VERSION ""

NS_ :

BS_:

BU_: AL DSC DSC_Sensor SZL

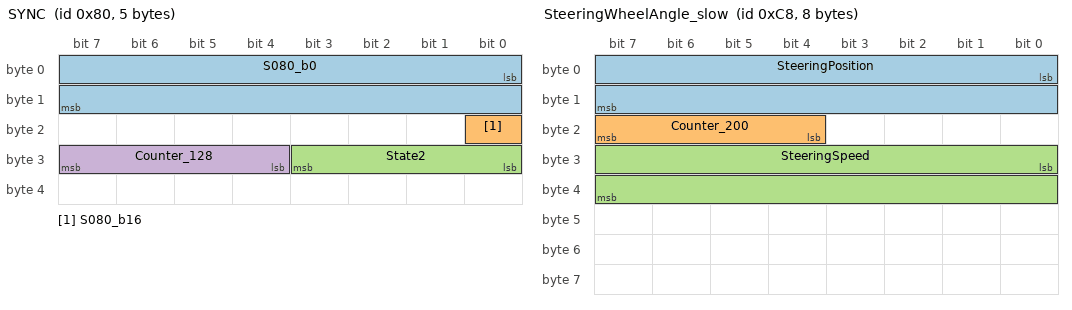
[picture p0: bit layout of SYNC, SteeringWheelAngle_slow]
BO_ 128 SYNC: 5 DSC
 SG_ S080_b0 : 0|16@1+ (1,0) [0|65535] "" Vector__XXX
 SG_ S080_b16 : 16|1@1+ (1,0) [0|1] "" Vector__XXX
 SG_ State2 : 24|4@1+ (1,0) [0|15] "" Vector__XXX
 SG_ Counter_128 : 28|4@1+ (1,0) [0|15] "" Vector__XXX

BO_ 195 SteeringWheelAngle_raw: 8 SZL

BO_ 200 SteeringWheelAngle_slow: 8 SZL
 SG_ SteeringPosition : 0|16@1- (0.04395,0) [-1440.1536|1440.10965] "deg" DSC
 SG_ Counter_200 : 20|4@1+ (1,0) [0|15] "" DSC
 SG_ SteeringSpeed : 24|16@1- (0.04395,0) [-1440.1536|1440.10965] "deg/s" DSC

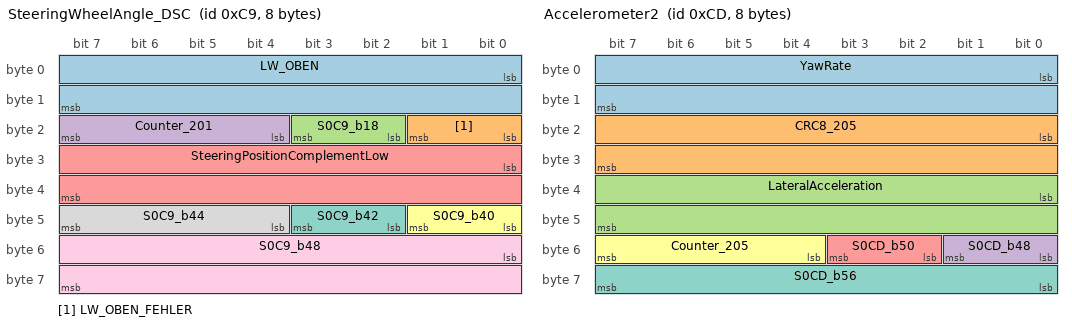
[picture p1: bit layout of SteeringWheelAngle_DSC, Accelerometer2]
BO_ 201 SteeringWheelAngle_DSC: 8 SZL
 SG_ LW_OBEN : 0|16@1- (0.04395,0) [-1440.1536|1440.10965] "deg" DSC
 SG_ LW_OBEN_FEHLER : 16|2@1+ (1,0) [0|3] "" DSC
 SG_ S0C9_b18 : 18|2@1+ (1,0) [0|3] "" DSC
 SG_ Counter_201 : 20|4@1+ (1,0) [0|15] "" DSC
 SG_ SteeringPositionComplementLow : 24|16@1- (1,0) [-32768|32767] "" DSC
 SG_ S0C9_b40 : 40|2@1+ (1,0) [0|3] "" DSC
 SG_ S0C9_b42 : 42|2@1+ (1,0) [0|3] "" DSC
 SG_ S0C9_b44 : 44|4@1+ (1,0) [0|15] "" DSC
 SG_ S0C9_b48 : 48|16@1+ (1,0) [0|65535] "" DSC

BO_ 205 Accelerometer2: 8 DSC_Sensor
 SG_ YawRate : 0|16@1- (1,0) [0|255] "" DSC
 SG_ CRC8_205 : 16|16@1- (1,0) [0|65535] "" DSC
 SG_ LateralAcceleration : 32|16@1- (1,0) [0|255] "" DSC
 SG_ S0CD_b48 : 48|2@1+ (1,0) [0|3] "" DSC
 SG_ S0CD_b50 : 50|2@1+ (1,0) [0|3] "" DSC
 SG_ Counter_205 : 52|4@1+ (1,0) [0|255] "" DSC
 SG_ S0CD_b56 : 56|8@1+ (1,0) [0|255] "" DSC

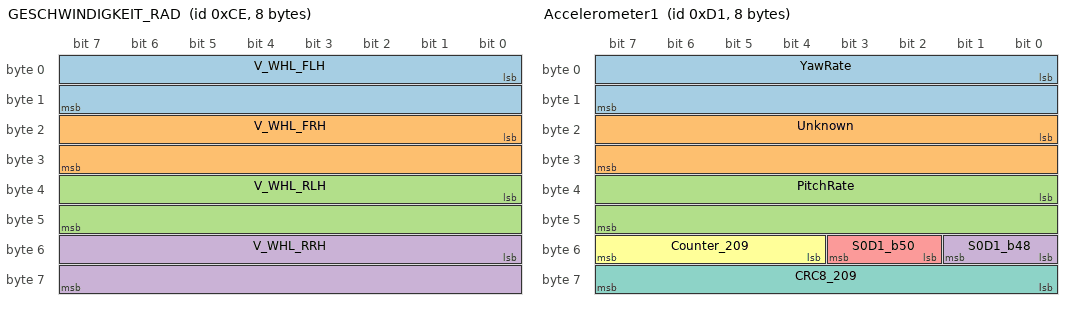
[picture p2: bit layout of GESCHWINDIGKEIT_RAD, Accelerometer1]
BO_ 206 GESCHWINDIGKEIT_RAD: 8 DSC
 SG_ V_WHL_FLH : 0|16@1- (0.0625,0) [-2048|2047.9375] "km/h" Vector__XXX
 SG_ V_WHL_FRH : 16|16@1- (0.0625,0) [-2048|2047.9375] "km/h" Vector__XXX
 SG_ V_WHL_RLH : 32|16@1- (0.0625,0) [-2048|2047.9375] "km/h" Vector__XXX
 SG_ V_WHL_RRH : 48|16@1- (0.0625,0) [-2048|2047.9375] "km/h" Vector__XXX

BO_ 209 Accelerometer1: 8 DSC_Sensor
 SG_ YawRate : 0|16@1- (1,0) [0|7] "" DSC
 SG_ Unknown : 16|16@1- (1,0) [0|65535] "" DSC
 SG_ PitchRate : 32|16@1- (1,0) [0|65535] "" DSC
 SG_ S0D1_b48 : 48|2@1+ (1,0) [0|3] "" DSC
 SG_ S0D1_b50 : 50|2@1+ (1,0) [0|3] "" DSC
 SG_ Counter_209 : 52|4@1+ (1,0) [0|255] "" DSC
 SG_ CRC8_209 : 56|8@1+ (1,0) [0|255] "" DSC

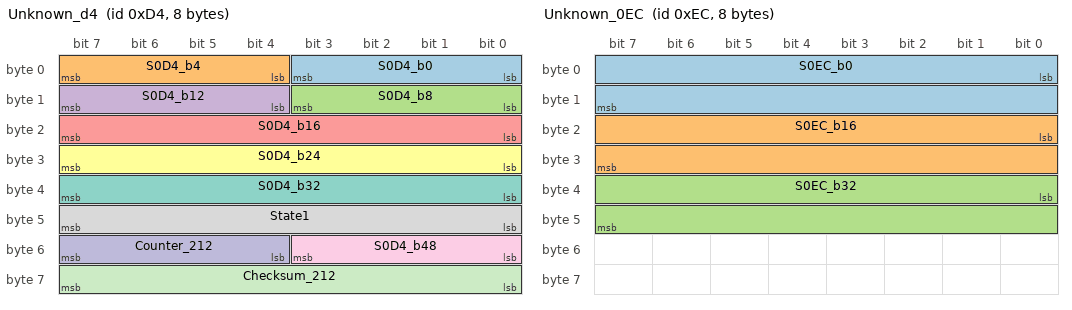
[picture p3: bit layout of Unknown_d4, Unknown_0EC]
BO_ 212 Unknown_d4: 8 DSC_Sensor
 SG_ S0D4_b0 : 0|4@1+ (1,0) [0|15] "" DSC
 SG_ S0D4_b4 : 4|4@1+ (1,0) [0|15] "" DSC
 SG_ S0D4_b8 : 8|4@1+ (1,0) [0|15] "" DSC
 SG_ S0D4_b12 : 12|4@1+ (1,0) [0|15] "" DSC
 SG_ S0D4_b16 : 16|8@1+ (1,0) [0|255] "" DSC
 SG_ S0D4_b24 : 24|8@1+ (1,0) [0|255] "" DSC
 SG_ S0D4_b32 : 32|8@1+ (1,0) [0|255] "" DSC
 SG_ State1 : 40|8@1+ (1,0) [0|255] "" DSC
 SG_ S0D4_b48 : 48|4@1+ (1,0) [0|15] "" DSC
 SG_ Counter_212 : 52|4@1+ (1,0) [0|255] "" DSC
 SG_ Checksum_212 : 56|8@1+ (1,0) [0|255] "" DSC

BO_ 236 Unknown_0EC: 8 Vector__XXX
 SG_ S0EC_b0 : 0|16@1+ (1,0) [0|65535] "" DSC
 SG_ S0EC_b16 : 16|16@1+ (1,0) [0|65535] "" DSC
 SG_ S0EC_b32 : 32|16@1+ (1,0) [0|65535] "" DSC

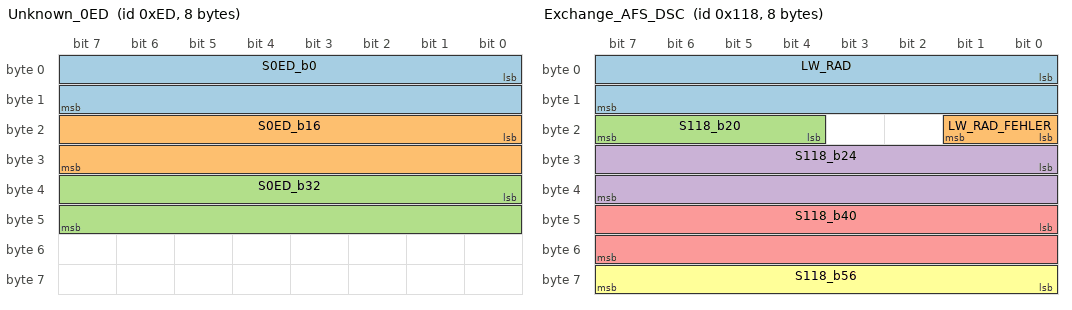
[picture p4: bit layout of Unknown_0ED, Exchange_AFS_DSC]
BO_ 237 Unknown_0ED: 8 Vector__XXX
 SG_ S0ED_b0 : 0|16@1+ (1,0) [0|65535] "" DSC
 SG_ S0ED_b16 : 16|16@1+ (1,0) [0|65535] "" DSC
 SG_ S0ED_b32 : 32|16@1+ (1,0) [0|65535] "" DSC

BO_ 239 Unknown_0EF: 8 Vector__XXX
 SG_ S0EF_b40 : 40|8@1+ (1,0) [0|255] "" DSC
 SG_ S0EF_b48 : 48|4@1+ (1,0) [0|15] "" DSC

BO_ 280 Exchange_AFS_DSC: 8 AL
 SG_ LW_RAD : 0|16@1- (0.04395,0) [-1440.1536|1440.10965] "deg" DSC
 SG_ LW_RAD_FEHLER : 16|2@1+ (1,0) [0|3] "" DSC
 SG_ S118_b20 : 20|4@1+ (1,0) [0|15] "" DSC
 SG_ S118_b24 : 24|16@1+ (1,0) [0|65535] "" DSC
 SG_ S118_b40 : 40|16@1+ (1,0) [0|65535] "" DSC
 SG_ S118_b56 : 56|8@1+ (1,0) [0|255] "" DSC

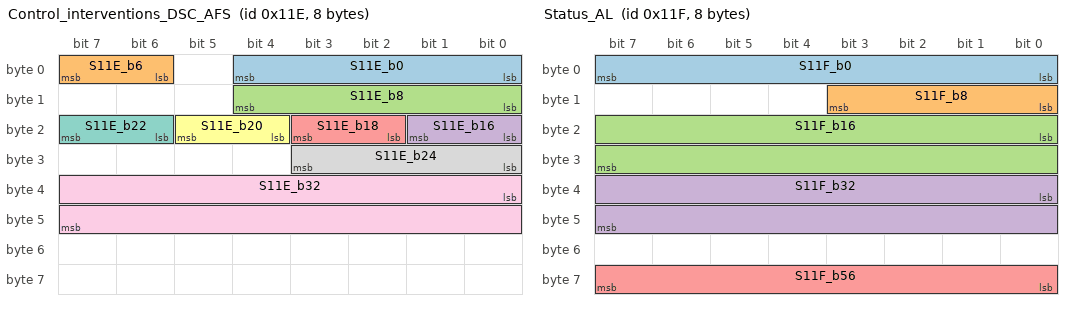
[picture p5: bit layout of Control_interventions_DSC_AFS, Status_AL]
BO_ 286 Control_interventions_DSC_AFS: 8 DSC
 SG_ S11E_b0 : 0|5@1+ (1,0) [0|31] "" Vector__XXX
 SG_ S11E_b6 : 6|2@1+ (1,0) [0|3] "" Vector__XXX
 SG_ S11E_b8 : 8|5@1+ (1,0) [0|31] "" Vector__XXX
 SG_ S11E_b16 : 16|2@1+ (1,0) [0|3] "" Vector__XXX
 SG_ S11E_b18 : 18|2@1+ (1,0) [0|3] "" Vector__XXX
 SG_ S11E_b20 : 20|2@1+ (1,0) [0|3] "" Vector__XXX
 SG_ S11E_b22 : 22|2@1+ (1,0) [0|3] "" Vector__XXX
 SG_ S11E_b24 : 24|4@1+ (1,0) [0|15] "" Vector__XXX
 SG_ S11E_b32 : 32|16@1+ (1,0) [0|65535] "" Vector__XXX

BO_ 287 Status_AL: 8 AL
 SG_ S11F_b0 : 0|8@1+ (1,0) [0|255] "" DSC
 SG_ S11F_b8 : 8|4@1+ (1,0) [0|15] "" DSC
 SG_ S11F_b16 : 16|16@1+ (1,0) [0|65535] "" DSC
 SG_ S11F_b32 : 32|16@1+ (1,0) [0|65535] "" DSC
 SG_ S11F_b56 : 56|8@1+ (1,0) [0|255] "" DSC

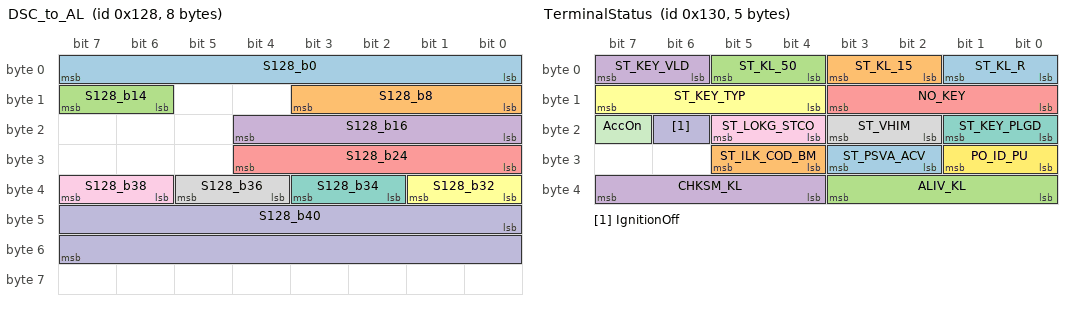
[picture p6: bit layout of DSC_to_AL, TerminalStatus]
BO_ 296 DSC_to_AL: 8 DSC
 SG_ S128_b0 : 0|8@1+ (1,0) [0|255] "" Vector__XXX
 SG_ S128_b8 : 8|4@1+ (1,0) [0|15] "" Vector__XXX
 SG_ S128_b14 : 14|2@1+ (1,0) [0|3] "" Vector__XXX
 SG_ S128_b16 : 16|5@1+ (1,0) [0|31] "" Vector__XXX
 SG_ S128_b24 : 24|5@1+ (1,0) [0|31] "" Vector__XXX
 SG_ S128_b32 : 32|2@1+ (1,0) [0|3] "" Vector__XXX
 SG_ S128_b34 : 34|2@1+ (1,0) [0|3] "" Vector__XXX
 SG_ S128_b36 : 36|2@1+ (1,0) [0|3] "" Vector__XXX
 SG_ S128_b38 : 38|2@1+ (1,0) [0|3] "" Vector__XXX
 SG_ S128_b40 : 40|16@1+ (1,0) [0|65535] "" Vector__XXX

BO_ 304 TerminalStatus: 5 DSC
 SG_ ST_KL_R : 0|2@1+ (1,0) [0|3] "" Vector__XXX
 SG_ ST_KL_15 : 2|2@1+ (1,0) [0|3] "" Vector__XXX
 SG_ ST_KL_50 : 4|2@1+ (1,0) [0|3] "" Vector__XXX
 SG_ ST_KEY_VLD : 6|2@1+ (1,0) [0|3] "" Vector__XXX
 SG_ NO_KEY : 8|4@1+ (1,0) [0|15] "" Vector__XXX
 SG_ ST_KEY_TYP : 12|4@1+ (1,0) [0|15] "" Vector__XXX
 SG_ ST_KEY_PLGD : 16|2@1+ (1,0) [0|3] "" Vector__XXX
 SG_ ST_VHIM : 18|2@1+ (1,0) [0|3] "" Vector__XXX
 SG_ ST_LOKG_STCO : 20|2@1+ (1,0) [0|3] "" Vector__XXX
 SG_ IgnitionOff : 22|1@1+ (1,0) [0|3] "" Vector__XXX
 SG_ AccOn : 23|1@1+ (1,0) [0|255] "" Vector__XXX
 SG_ PO_ID_PU : 24|2@1+ (1,0) [0|3] "" Vector__XXX
 SG_ ST_PSVA_ACV : 26|2@1+ (1,0) [0|3] "" Vector__XXX
 SG_ ST_ILK_COD_BM : 28|2@1+ (1,0) [0|3] "" Vector__XXX
 SG_ ALIV_KL : 32|4@1+ (1,0) [0|15] "" Vector__XXX
 SG_ CHKSM_KL : 36|4@1+ (1,0) [0|15] "" Vector__XXX

BO_ 320 Unknown140: 2 Vector__XXX
 SG_ S140_b0 : 0|16@1+ (1,0) [0|65535] "" DSC

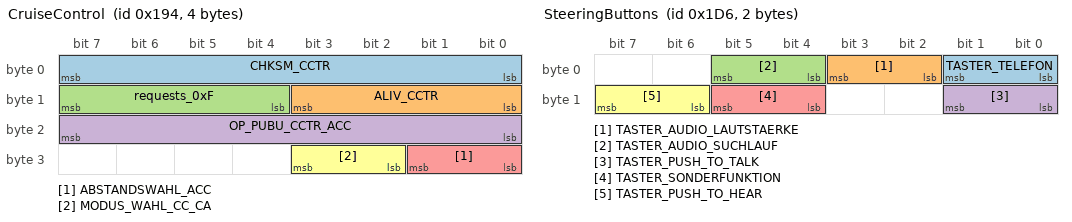
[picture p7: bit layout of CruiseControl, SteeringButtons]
BO_ 404 CruiseControl: 4 SZL
 SG_ CHKSM_CCTR : 7|8@0+ (1,0) [0|255] "" DSC
 SG_ ALIV_CCTR : 11|4@0+ (1,0) [0|15] "" DSC
 SG_ requests_0xF : 15|4@0+ (1,0) [0|15] "" DSC
 SG_ OP_PUBU_CCTR_ACC : 16|8@1+ (1,0) [0|255] "" DSC
 SG_ ABSTANDSWAHL_ACC : 24|2@1+ (1,0) [0|3] "" DSC
 SG_ MODUS_WAHL_CC_CA : 26|2@1+ (1,0) [0|3] "" DSC

BO_ 470 SteeringButtons: 2 SZL
 SG_ TASTER_TELEFON : 0|2@1+ (1,0) [0|3] "" DSC
 SG_ TASTER_AUDIO_LAUTSTAERKE : 2|2@1+ (1,0) [0|3] "" DSC
 SG_ TASTER_AUDIO_SUCHLAUF : 4|2@1+ (1,0) [0|3] "" DSC
 SG_ TASTER_PUSH_TO_TALK : 8|2@1+ (1,0) [0|3] "" DSC
 SG_ TASTER_SONDERFUNKTION : 12|2@1+ (1,0) [0|3] "" DSC
 SG_ TASTER_PUSH_TO_HEAR : 14|2@1+ (1,0) [0|3] "" DSC

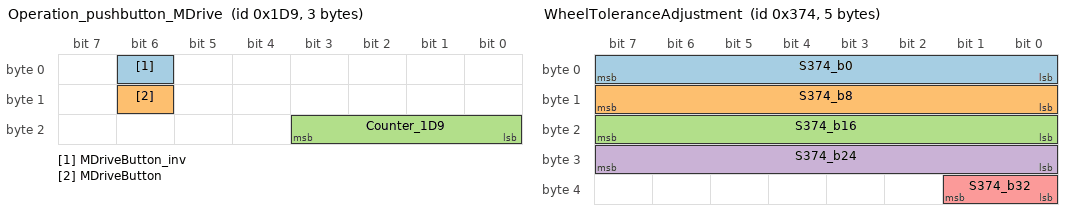
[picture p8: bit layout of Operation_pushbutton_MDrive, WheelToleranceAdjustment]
BO_ 473 Operation_pushbutton_MDrive: 3 SZL
 SG_ MDriveButton_inv : 6|1@1+ (1,0) [0|1] "" DSC
 SG_ MDriveButton : 14|1@1+ (1,0) [0|1] "" DSC
 SG_ Counter_1D9 : 16|4@1+ (1,0) [0|15] "" DSC

BO_ 678 WiperSwitch: 2 SZL
 SG_ WISCHERTASTER : 0|8@1+ (1,0) [0|255] "" DSC
 SG_ WISCHERPOTI : 8|3@1+ (1,0) [0|7] "" DSC

BO_ 884 WheelToleranceAdjustment: 5 DSC
 SG_ S374_b0 : 0|8@1+ (1,0) [0|255] "" Vector__XXX
 SG_ S374_b8 : 8|8@1+ (1,0) [0|255] "" Vector__XXX
 SG_ S374_b16 : 16|8@1+ (1,0) [0|255] "" Vector__XXX
 SG_ S374_b24 : 24|8@1+ (1,0) [0|255] "" Vector__XXX
 SG_ S374_b32 : 32|2@1+ (1,0) [0|3] "" Vector__XXX

BO_ 1934 Conti_Internal_78E: 8 Vector__XXX

BO_ 1935 Conti_Internal_78F: 8 Vector__XXX

BO_ 1936 Conti_Internal_790: 8 DSC

BO_ 1937 Conti_Internal_791: 8 DSC

BO_ 1943 Conti_Internal_797: 8 DSC

BO_ 1944 Conti_Internal_798: 8 DSC

BO_ 2004 Conti_Internal_7D4: 8 DSC

BO_ 2005 Conti_Internal_7D5: 8 DSC

BO_ 2006 Conti_Internal_7D6: 8 DSC

BO_ 2007 Conti_Internal_7D7: 8 DSC

BO_ 2008 Conti_Internal_7D8: 8 DSC

BO_ 2012 Conti_Internal_7DC: 8 Vector__XXX

BO_ 2013 Conti_Internal_7DD: 8 Vector__XXX

BO_ 2014 Conti_Internal_7DE: 8 Vector__XXX

BO_ 2015 Conti_Internal_7DF: 8 Vector__XXX

CM_ "BMW E8x/E9x F-CAN (chassis CAN, 500 kbit/s) with MK60E5 DSC, all known frames. Generated by build_full_dbc.py. Reference: MK60E5 SPdaten (firmware tables, DSC_87.prg) and MEVD17.2 function description; verified against a 320i PT-CAN log and an E92 M3 K-CAN trace; secondary: E65_ReverseEngineering docs, NewTIS, superwofy frame notes, community DBC. See BMW_E9x_full_DBC_report.md";
CM_ BO_ 128 "MK60E5 FW 7846816A (M3): DSC TX, event | DSC DTC C99B: C99B - F-CAN SSL Sync, no communication with DSC, timeout. [DE: C99B - F-CAN SZL Sync, keine Kommunikation mit DSC, Timeout.] (supervised: timeout)";
CM_ SG_ 128 S080_b0 "MK60E5 FW 7846816A (M3) signal (internal var 0x00), meaning unknown";
CM_ SG_ 128 S080_b16 "MK60E5 FW 7846816A (M3) signal (internal var 0x0C), meaning unknown | community DBC defined State1 16|8@1 here";
CM_ BO_ 195 "DSC DTC D374: D374 - F-CAN SWA raw sensor message 195 missing [DE: D374 - F-CAN SWA-Raw-Sensor Botschaft 195 fehlt] (supervised: checksum, alive, timeout)";
CM_ BO_ 200 "MK60E5 FW 7846816A (M3): DSC RX | Firmware comparison: not in MK60E5 FW 6862873A | DSC DTC D373: D373 - F-CAN SWA-top sensor message 200 or 201 missing [DE: D373 - F-CAN SWA-Top-Sensor Botschaft 200 oder 201 fehlt] (supervised: checksum, alive, timeout) | M3 firmware: received and copied to PT-CAN 0x0C8 by the DSC's F-CAN -> PT-CAN gateway, shortened to DLC 6 and only every 20th 10 ms cycle (200 ms); no signals mapped";
CM_ SG_ 200 SteeringPosition "Scale 0.04395 deg per bit (angle: same raw value in 0x0C4 (DSC) and 0x0C8 (SZL) in the E92 M3 K-CAN trace; same unit as F-CAN 0x0C9 LW_OBEN (DSC_87.prg) assumed (inference); E65 doc STWA); previous community factor 0.0428317";
CM_ SG_ 200 SteeringSpeed "Scale 0.04395 deg/s per bit (angle rate: scale from the E65 doc (STWA_V), not verified on E9x); previous community factor 0.0428317";
CM_ BO_ 201 "MK60E5 FW 7846816A (M3): DSC RX | Firmware comparison: MK60E5 FW 6862873A also maps 42|2 | DSC DTC D373: D373 - F-CAN SWA-top sensor message 200 or 201 missing [DE: D373 - F-CAN SWA-Top-Sensor Botschaft 200 oder 201 fehlt] (supervised: checksum, alive, timeout) | Steering angle from SZL (optical steering-angle sensor). DSC_87.prg job STATUS_F_CAN_LW / table F_CAN_LW (steering-angle / wheel-angle verification status). NCS coding block 0x3001 'SZL' selects the SZL variant (E8x/E9x, with/without AFS)";
CM_ SG_ 201 LW_OBEN "previous name (community DBC): SteeringPosition | DSC_87.prg job STATUS_F_CAN_LW result STAT_LW_OBEN_WERT (Lenkradwinkel_Oben aus F_CAN Telegramm)";
CM_ SG_ 201 LW_OBEN_FEHLER "MK60E5 FW 7846816A (M3) signal (internal var 0x20), meaning unknown | previous name (firmware field): S0C9_b16 | DSC_87.prg job STATUS_F_CAN_LW result STAT_LW_OBEN_FEHLER_WERT (Status des Signals Lenkradwinkel_Oben aus F_CAN Telegramm); value table SGBD";
CM_ SG_ 201 S0C9_b18 "MK60E5 FW 7846816A (M3) signal (internal var 0x21), meaning unknown";
CM_ SG_ 201 S0C9_b40 "MK60E5 FW 7846816A (M3) signal (internal var 0x24), meaning unknown";
CM_ SG_ 201 S0C9_b42 "MK60E5 FW 6862873A signal (internal var 0x46), meaning unknown";
CM_ SG_ 201 S0C9_b44 "MK60E5 FW 7846816A (M3) signal (internal var 0x23), meaning unknown";
CM_ SG_ 201 S0C9_b48 "MK60E5 FW 7846816A (M3) signal (internal var 0x25), meaning unknown";
CM_ BO_ 205 "MK60E5 FW 7846816A (M3): DSC RX | Firmware comparison: MK60E5 FW 6862873A also maps 56|8 | DSC DTC D370: D370 - F-CAN Sensorcluster_1 message 205 missing [DE: D370 - F-CAN Sensorcluster_1 Botschaft 205 fehlt] (supervised: checksum, alive, timeout) | TIS: redundant DSC sensor (Active Steering) sends 2x yaw rate + 2x lateral acceleration; 0x0CD/0x0D1 share one layout (inference: one frame per channel). DSC_87.prg table SENSOR_CLUSTER: VDO single, Systron Donner single, Systron Donner redundant";
CM_ SG_ 205 S0CD_b48 "MK60E5 FW 7846816A (M3) signal (internal var 0x2B), meaning unknown";
CM_ SG_ 205 S0CD_b50 "MK60E5 FW 7846816A (M3) signal (internal var 0x2C), meaning unknown";
CM_ SG_ 205 S0CD_b56 "MK60E5 FW 6862873A signal (internal var 0x06), meaning unknown";
CM_ BO_ 206 "MK60E5 FW 7846816A (M3): DSC TX, cycle 10 ms | DSC DTC C994: C994 - (not receive message in administrable time) F-CAN SSL wheel speed communication with DSC, Timeout [DE: C994 - F-CAN SZL Radgeschwindigkeit, Kommunikation mit DSC, Timeout (Nachricht in applizierbarer Zeit nicht empfangen)] (supervised: timeout) | DSC DTC C995: C995 - F-CAN SSL wheel speed plausibility, communication with DSC, wheel speed> 300 km / h [DE: C995 - F-CAN SZL Radgeschwindigkeit Plausibilitaet, Kommunikation mit DSC, Radgeschwindigkeit >300km/h] (supervised: range) | DSC DTC C996: C996 - F-CAN SSL wheel speed plausibility, communication with DSC, wheel speed <300km / h [DE: C996 - F-CAN SZL Radgeschwindigkeit Plausibilitaet, Kommunikation mit DSC, Radgeschwindigkeit <300km/h] (supervised: range) | E65 doc: 'Wheel rotating speed', DLC 8, cycle 20 ms";
CM_ SG_ 206 V_WHL_FLH "BMW name V_WHL_FLH - E65 doc (HeinrichG-V12/E65_ReverseEngineering, Bosch MED9.2.1)";
CM_ SG_ 206 V_WHL_FRH "BMW name V_WHL_FRH - E65 doc (HeinrichG-V12/E65_ReverseEngineering, Bosch MED9.2.1)";
CM_ SG_ 206 V_WHL_RLH "BMW name V_WHL_RLH - E65 doc (HeinrichG-V12/E65_ReverseEngineering, Bosch MED9.2.1)";
CM_ SG_ 206 V_WHL_RRH "BMW name V_WHL_RRH - E65 doc (HeinrichG-V12/E65_ReverseEngineering, Bosch MED9.2.1)";
CM_ BO_ 209 "MK60E5 FW 7846816A (M3): DSC RX | Firmware comparison: MK60E5 FW 6862873A also maps 56|8 | DSC DTC D371: D371 - missing F-CAN message Sensorcluster_2 209 [DE: D371 - F-CAN Sensorcluster_2 Botschaft 209 fehlt] (supervised: checksum, alive, timeout) | TIS: second channel of the redundant DSC sensor (inference, see 0x0CD)";
CM_ SG_ 209 S0D1_b48 "MK60E5 FW 7846816A (M3) signal (internal var 0x31), meaning unknown";
CM_ SG_ 209 S0D1_b50 "MK60E5 FW 7846816A (M3) signal (internal var 0x33), meaning unknown";
CM_ BO_ 212 "MK60E5 FW 7846816A (M3): DSC RX | Firmware comparison: MK60E5 FW 6862873A also maps 56|8 | DSC DTC D372: D372 - F-CAN Sensorcluster_3 message 212 missing [DE: D372 - F-CAN Sensorcluster_3 Botschaft 212 fehlt] (supervised: checksum, alive, timeout)";
CM_ SG_ 212 S0D4_b0 "MK60E5 FW 7846816A (M3) signal (internal var 0x3D), meaning unknown";
CM_ SG_ 212 S0D4_b4 "MK60E5 FW 7846816A (M3) signal (internal var 0x34), meaning unknown";
CM_ SG_ 212 S0D4_b8 "MK60E5 FW 7846816A (M3) signal (internal var 0x36), meaning unknown";
CM_ SG_ 212 S0D4_b12 "MK60E5 FW 7846816A (M3) signal (internal var 0x37), meaning unknown";
CM_ SG_ 212 S0D4_b16 "MK60E5 FW 7846816A (M3) signal (internal var 0x35), meaning unknown";
CM_ SG_ 212 S0D4_b24 "MK60E5 FW 7846816A (M3) signal (internal var 0x38), meaning unknown";
CM_ SG_ 212 S0D4_b32 "MK60E5 FW 7846816A (M3) signal (internal var 0x39), meaning unknown";
CM_ SG_ 212 S0D4_b48 "MK60E5 FW 7846816A (M3) signal (internal var 0x3B), meaning unknown";
CM_ BO_ 236 "MK60E5 FW 6862873A: DSC RX | Firmware comparison: only in MK60E5 FW 6862873A";
CM_ SG_ 236 S0EC_b0 "MK60E5 FW 6862873A signal (internal var 0x02), meaning unknown";
CM_ SG_ 236 S0EC_b16 "MK60E5 FW 6862873A signal (internal var 0x51), meaning unknown";
CM_ SG_ 236 S0EC_b32 "MK60E5 FW 6862873A signal (internal var 0x4D), meaning unknown";
CM_ BO_ 237 "MK60E5 FW 6862873A: DSC RX | Firmware comparison: only in MK60E5 FW 6862873A";
CM_ SG_ 237 S0ED_b0 "MK60E5 FW 6862873A signal (internal var 0x32), meaning unknown";
CM_ SG_ 237 S0ED_b16 "MK60E5 FW 6862873A signal (internal var 0x53), meaning unknown";
CM_ SG_ 237 S0ED_b32 "MK60E5 FW 6862873A signal (internal var 0x4F), meaning unknown";
CM_ BO_ 239 "MK60E5 FW 6862873A: DSC RX | Firmware comparison: only in MK60E5 FW 6862873A";
CM_ SG_ 239 S0EF_b40 "MK60E5 FW 6862873A signal (internal var 0x34), meaning unknown";
CM_ SG_ 239 S0EF_b48 "MK60E5 FW 6862873A signal (internal var 0x27), meaning unknown";
CM_ BO_ 280 "MK60E5 FW 7846816A (M3): DSC RX | Firmware comparison: MK60E5 FW 6862873A also maps 56|8 | DSC DTC D375: D375 - F-CAN AFS - exchange AFS DSC message 118 missing [DE: D375 - F-CAN AFS - Austausch AFS-DSC Botschaft 118 fehlt] (supervised: checksum, alive, timeout) | Active Steering (AL/AFS) <-> DSC exchange. DSC_87.prg job STATUS_F_CAN_LW reads it as 'Lenkwinkel_Rad' (road-wheel steering angle from AFS) + its status";
CM_ SG_ 280 LW_RAD "MK60E5 FW 7846816A (M3) signal (internal var 0x4D), meaning unknown | previous name (firmware field): S118_b0 | DSC_87.prg job STATUS_F_CAN_LW result STAT_LW_RAD_WERT (Lenkwinkel_Rad aus F_CAN Telegramm)";
CM_ SG_ 280 LW_RAD_FEHLER "MK60E5 FW 7846816A (M3) signal (internal var 0x1E), meaning unknown | previous name (firmware field): S118_b16 | DSC_87.prg job STATUS_F_CAN_LW result STAT_LW_RAD_FEHLER_WERT (Status des Signals Radlenkwinkel fuer AFS aus F_CAN Telegramm); value table SGBD";
CM_ SG_ 280 S118_b20 "MK60E5 FW 7846816A (M3) signal (internal var 0x4C), meaning unknown";
CM_ SG_ 280 S118_b24 "MK60E5 FW 7846816A (M3) signal (internal var 0x1D), meaning unknown";
CM_ SG_ 280 S118_b40 "MK60E5 FW 7846816A (M3) signal (internal var 0x1F), meaning unknown";
CM_ SG_ 280 S118_b56 "MK60E5 FW 6862873A signal (internal var 0x2C), meaning unknown";
CM_ BO_ 286 "MK60E5 FW 7846816A (M3): DSC TX, cycle 10 ms | Firmware comparison: not in MK60E5 FW 6862873A | M3 firmware only (replaces 0x128 of 6862873A in the table; similar structure: two 5-bit values, four 2-bit qualifiers, one 16-bit value - meaning unknown)";
CM_ SG_ 286 S11E_b0 "MK60E5 FW 7846816A (M3) signal (internal var 0x0B), meaning unknown";
CM_ SG_ 286 S11E_b6 "MK60E5 FW 7846816A (M3) signal (internal var 0x14), meaning unknown";
CM_ SG_ 286 S11E_b8 "MK60E5 FW 7846816A (M3) signal (internal var 0x13), meaning unknown";
CM_ SG_ 286 S11E_b16 "MK60E5 FW 7846816A (M3) signal (internal var 0x07), meaning unknown";
CM_ SG_ 286 S11E_b18 "MK60E5 FW 7846816A (M3) signal (internal var 0x1C), meaning unknown";
CM_ SG_ 286 S11E_b20 "MK60E5 FW 7846816A (M3) signal (internal var 0x1B), meaning unknown";
CM_ SG_ 286 S11E_b22 "MK60E5 FW 7846816A (M3) signal (internal var 0x1A), meaning unknown";
CM_ SG_ 286 S11E_b24 "MK60E5 FW 7846816A (M3) signal (internal var 0x19), meaning unknown";
CM_ SG_ 286 S11E_b32 "MK60E5 FW 7846816A (M3) signal (internal var 0x16), meaning unknown";
CM_ BO_ 287 "MK60E5 FW 7846816A (M3): DSC RX | Firmware comparison: MK60E5 FW 6862873A also maps 56|8 | DSC DTC D376: D376 - F-CAN AFS message 11F missing [DE: D376 - F-CAN AFS Botschaft 11F fehlt] (supervised: checksum, alive, timeout)";
CM_ SG_ 287 S11F_b0 "MK60E5 FW 7846816A (M3) signal (internal var 0x46), meaning unknown";
CM_ SG_ 287 S11F_b8 "MK60E5 FW 7846816A (M3) signal (internal var 0x4A), meaning unknown";
CM_ SG_ 287 S11F_b16 "MK60E5 FW 7846816A (M3) signal (internal var 0x49), meaning unknown";
CM_ SG_ 287 S11F_b32 "MK60E5 FW 7846816A (M3) signal (internal var 0x47), meaning unknown";
CM_ SG_ 287 S11F_b56 "MK60E5 FW 6862873A signal (internal var 0x03), meaning unknown";
CM_ BO_ 296 "MK60E5 FW 6862873A: DSC TX, cycle 10 ms | Firmware comparison: only in MK60E5 FW 6862873A | Probably the yaw-moment compensation correction angle DSC -> Active Steering (TIS; inference). Only in 6862873A; the M3 firmware (no Active Steering) sends 0x11E instead";
CM_ SG_ 296 S128_b0 "MK60E5 FW 6862873A signal (internal var 0x07), meaning unknown";
CM_ SG_ 296 S128_b8 "MK60E5 FW 6862873A signal (internal var 0x0C), meaning unknown";
CM_ SG_ 296 S128_b14 "MK60E5 FW 6862873A signal (internal var 0x1C), meaning unknown";
CM_ SG_ 296 S128_b16 "MK60E5 FW 6862873A signal (internal var 0x0D), meaning unknown";
CM_ SG_ 296 S128_b24 "MK60E5 FW 6862873A signal (internal var 0x09), meaning unknown";
CM_ SG_ 296 S128_b32 "MK60E5 FW 6862873A signal (internal var 0x0A), meaning unknown";
CM_ SG_ 296 S128_b34 "MK60E5 FW 6862873A signal (internal var 0x0F), meaning unknown";
CM_ SG_ 296 S128_b36 "MK60E5 FW 6862873A signal (internal var 0x10), meaning unknown";
CM_ SG_ 296 S128_b38 "MK60E5 FW 6862873A signal (internal var 0x11), meaning unknown";
CM_ SG_ 296 S128_b40 "MK60E5 FW 6862873A signal (internal var 0x12), meaning unknown";
CM_ BO_ 304 "MK60E5 FW 7846816A (M3): DSC TX, event | DSC DTC C99C: C99C - F-CAN SSL, terminal status, no communication with DSC, timeout. [DE: C99C - F-CAN SZL, Klemmenstatus, keine Kommunikation mit DSC, Timeout.] (supervised: timeout) | E65 doc: 'Terminal status', DLC 5, cycle 100 ms | E65 defines ST_KLCK 22|2 here; existing signals kept: 320i log has raw 2 (E65: 'signal invalid') with the engine running; E9x CAS differs | cycle time source: E65 doc";
CM_ SG_ 304 ST_KL_R "BMW name ST_KL_R - E65 doc (HeinrichG-V12/E65_ReverseEngineering, Bosch MED9.2.1); E65 definition, not yet verified on E9x";
CM_ SG_ 304 ST_KL_15 "BMW name ST_KL_15 - E65 doc (HeinrichG-V12/E65_ReverseEngineering, Bosch MED9.2.1); E65 definition, not yet verified on E9x";
CM_ SG_ 304 ST_KL_50 "BMW name ST_KL_50 - E65 doc (HeinrichG-V12/E65_ReverseEngineering, Bosch MED9.2.1); E65 definition, not yet verified on E9x";
CM_ SG_ 304 ST_KEY_VLD "BMW name ST_KEY_VLD - E65 doc (HeinrichG-V12/E65_ReverseEngineering, Bosch MED9.2.1); E65 definition, not yet verified on E9x";
CM_ SG_ 304 NO_KEY "BMW name NO_KEY - E65 doc (HeinrichG-V12/E65_ReverseEngineering, Bosch MED9.2.1); E65 definition, not yet verified on E9x";
CM_ SG_ 304 ST_KEY_TYP "BMW name ST_KEY_TYP - E65 doc (HeinrichG-V12/E65_ReverseEngineering, Bosch MED9.2.1); E65 definition, not yet verified on E9x";
CM_ SG_ 304 ST_KEY_PLGD "BMW name ST_KEY_PLGD - E65 doc (HeinrichG-V12/E65_ReverseEngineering, Bosch MED9.2.1); E65 definition, not yet verified on E9x";
CM_ SG_ 304 ST_VHIM "BMW name ST_VHIM - E65 doc (HeinrichG-V12/E65_ReverseEngineering, Bosch MED9.2.1); E65 definition, not yet verified on E9x";
CM_ SG_ 304 ST_LOKG_STCO "BMW name ST_LOKG_STCO - E65 doc (HeinrichG-V12/E65_ReverseEngineering, Bosch MED9.2.1); E65 definition, not yet verified on E9x";
CM_ SG_ 304 PO_ID_PU "BMW name PO_ID_PU - E65 doc (HeinrichG-V12/E65_ReverseEngineering, Bosch MED9.2.1); E65 definition, not yet verified on E9x";
CM_ SG_ 304 ST_PSVA_ACV "BMW name ST_PSVA_ACV - E65 doc (HeinrichG-V12/E65_ReverseEngineering, Bosch MED9.2.1); E65 definition, not yet verified on E9x";
CM_ SG_ 304 ST_ILK_COD_BM "BMW name ST_ILK_COD_BM - E65 doc (HeinrichG-V12/E65_ReverseEngineering, Bosch MED9.2.1); E65 definition, not yet verified on E9x";
CM_ SG_ 304 ALIV_KL "previous name (community DBC): Counter_304 | BMW name ALIV_KL - E65 doc (HeinrichG-V12/E65_ReverseEngineering, Bosch MED9.2.1)";
CM_ SG_ 304 CHKSM_KL "previous name (community DBC): Checksum_304 | BMW name CHKSM_KL - E65 doc (HeinrichG-V12/E65_ReverseEngineering, Bosch MED9.2.1)";
CM_ BO_ 320 "MK60E5 FW 7846816A (M3): DSC RX | Sensor cluster identification: byte 0 = cluster type (DSC_87.prg job STATUS_F_CAN_TYP_SENSORCLUSTER, request 22 01 40)";
CM_ SG_ 320 S140_b0 "MK60E5 FW 7846816A (M3) signal (internal var 0x04), meaning unknown | bits 0|8: CLUSTER_TYP - DSC_87.prg job STATUS_F_CAN_TYP_SENSORCLUSTER result STAT_CLUSTER_TYP_WERT (Typ des Sensorclusters); value table SGBD (1=Sensor Cluster VDO einfach; 2=Sensor Cluster SYSTRON DONNER einfach; 3=Sensor Cluster SYSTRON DONNER redundant; 255=Signal ungueltig)";
CM_ BO_ 404 "MK60E5 FW 7846816A (M3): DSC RX | Cruise-control stalk; DSC_87.prg job STATUS_F_CAN_TEMPOMAT_ACC decodes it with table TEMP_ACC (tip forward/back, push through, tip up/down, axial tip, mode button). Byte 2 (bits 16-23) is evaluated in priority order by BMW: 0xFF invalid; (b & 0x7F) == 0 no action; (b & 0xB0) == 0x10 tip down; (b & 0xB0) == 0x90 tip up; bit 6 axial tip; else low nibble 1 tip forward, 2 push forward, 4 tip back, 8 pull back (other values undefined) | E65 doc: 'Operation cruise control / ACC', DLC 4, cycle 200 ms | cycle time source: E65 doc";
CM_ SG_ 404 CHKSM_CCTR "BMW 8-bit checksum without ID: s = sum(other bytes) + 0; chk = (s & 0xFF) + (s >> 8) - verified 100 % in the 320i log and two E65 logs | previous name (community DBC): Checksum_404 | BMW name CHKSM_CCTR - E65 doc (HeinrichG-V12/E65_ReverseEngineering, Bosch MED9.2.1)";
CM_ SG_ 404 ALIV_CCTR "Message is sent at higher rate when cruise stalk is pressed | previous name (community DBC): Counter_404 | BMW name ALIV_CCTR - E65 doc (HeinrichG-V12/E65_ReverseEngineering, Bosch MED9.2.1)";
CM_ SG_ 404 OP_PUBU_CCTR_ACC "MK60E5 FW 7846816A (M3) signal (internal var 0x3F), meaning unknown | community DBC flags here: bit 16 = plus1mph_request, bit 17 = plus5mph_request, bit 18 = minus1mph_request, bit 19 = minus5mph_request, bit 20 = Cancel_request_up_or_down_stalk, bit 22 = Resume_request, bit 23 = Cancel_request_up_stalk | previous name (firmware field): S194_b16 | BMW name OP_PUBU_CCTR_ACC - E65 doc (HeinrichG-V12/E65_ReverseEngineering, Bosch MED9.2.1); one-hot enum; community DBC flags: bit 16 plus1mph, 17 plus5mph, 18 minus1mph, 19 minus5mph, 20 cancel, 22 resume | SGBD name TASTER_TEMPOMAT_ACC; DSC_87.prg job STATUS_F_CAN_TEMPOMAT_ACC result STAT_TASTER_TEMPOMAT_ACC (ACC_Status aus F_CAN Telegramm); value table SGBD";
CM_ SG_ 404 ABSTANDSWAHL_ACC "MK60E5 FW 7846816A (M3) signal (internal var 0x40), meaning unknown | previous name (firmware field): S194_b24 | DSC_87.prg job STATUS_F_CAN_TEMPOMAT_ACC result STAT_ABSTANDSWAHL_ACC (ACC_Status aus F_CAN Telegramm); value table SGBD";
CM_ SG_ 404 MODUS_WAHL_CC_CA "MK60E5 FW 7846816A (M3) signal (internal var 0x41), meaning unknown | previous name (firmware field): S194_b26 | DSC_87.prg job STATUS_F_CAN_TEMPOMAT_ACC result STAT_MODUS_WAHL_CC_CA (ACC_Status aus F_CAN Telegramm); value table SGBD";
CM_ BO_ 470 "MK60E5 FW 7846816A (M3): DSC RX | Steering-wheel buttons; DSC_87.prg job STATUS_F_CAN_TASTER_AUDIO_TEL / table AUDIO_TEL (TEL, volume, search, PTT, horn, special, PTH)";
CM_ SG_ 470 TASTER_TELEFON "DSC_87.prg job STATUS_F_CAN_TASTER_AUDIO_TEL result STAT_TASTER_TELEFON (TEL_Status aus F_CAN Telegramm); value table SGBD | replaces community signals Telephone 0|1";
CM_ SG_ 470 TASTER_AUDIO_LAUTSTAERKE "DSC_87.prg job STATUS_F_CAN_TASTER_AUDIO_TEL result STAT_TASTER_AUDIO_LAUTSTAERKE (TEL_Status aus F_CAN Telegramm); value table SGBD | replaces community signals Volume_UP 3|1, Volume_DOWN 2|1";
CM_ SG_ 470 TASTER_AUDIO_SUCHLAUF "DSC_87.prg job STATUS_F_CAN_TASTER_AUDIO_TEL result STAT_TASTER_AUDIO_SUCHLAUF (TEL_Status aus F_CAN Telegramm); value table SGBD | replaces community signals Next_up 5|1, Previous_down 4|1";
CM_ SG_ 470 TASTER_PUSH_TO_TALK "DSC_87.prg job STATUS_F_CAN_TASTER_AUDIO_TEL result STAT_TASTER_PUSH_TO_TALK (TEL_Status aus F_CAN Telegramm); value table SGBD | replaces community signals VoiceControl 8|1";
CM_ SG_ 470 TASTER_SONDERFUNKTION "DSC_87.prg job STATUS_F_CAN_TASTER_AUDIO_TEL result STAT_TASTER_SONDERFUNKTION (TEL_Status aus F_CAN Telegramm); value table SGBD";
CM_ SG_ 470 TASTER_PUSH_TO_HEAR "DSC_87.prg job STATUS_F_CAN_TASTER_AUDIO_TEL result STAT_TASTER_PUSH_TO_HEAR (TEL_Status aus F_CAN Telegramm); value table SGBD";
CM_ BO_ 473 "MK60E5 FW 7846816A (M3): DSC RX | Firmware comparison: not in MK60E5 FW 6862873A | M3 firmware only: received and copied unchanged to PT-CAN 0x1D9 by the DSC's F-CAN -> PT-CAN gateway (fcan_rx_queue_push 0xC56D0 -> drain 0x7A172; no signals mapped). SPdaten JBBF70.prg (CAN ID table): 'Bedienung Taster M-Drive' from SZL = steering-wheel M-Drive button";
CM_ SG_ 473 MDriveButton_inv "superwofy/E9X-M-CAN-Integration-Module notes (MIT) (0x1D9 Steering Wheel M button status.txt): byte 0 = 0xFF released, 0xBF pressed";
CM_ SG_ 473 MDriveButton "superwofy/E9X-M-CAN-Integration-Module notes (MIT) (0x1D9 Steering Wheel M button status.txt): byte 1 = 0x3F released, 0x7F pressed";
CM_ SG_ 473 Counter_1D9 "superwofy/E9X-M-CAN-Integration-Module notes (MIT) (0x1D9 Steering Wheel M button status.txt): low nibble of byte 2 counts 0..15; sent every 1 s, every 100 ms while the button is pressed";
CM_ BO_ 678 "MK60E5 FW 7846816A (M3): DSC RX | TIS: wiper switch position drives DSC brake-disc drying. DSC_87.prg job STATUS_F_CAN_WISCHERTASTER / table WISCHER (interval/auto, stage 1/2, tip wipe, front/rear wash, rear wipe, rain-sensor stage). Byte 0 is evaluated in priority order by BMW: 0xFF invalid; 0 no action; bit 7 rear wash; bit 6 rear wipe; bit 4 front wash; bit 3 tip wipe; else bits 0-1: 1 interval/auto, 2 stage 1, 3 stage 2 (bits 2 and 5 ignored)";
CM_ SG_ 678 WISCHERTASTER "MK60E5 FW 7846816A (M3) signal (internal var 0x44), meaning unknown | community DBC flags here: bit 0 = AutoWipersOn | previous name (firmware field): S2A6_b0 | DSC_87.prg job STATUS_F_CAN_WISCHERTASTER result STAT_WISCHERTASTER (Status_Bit aus SG Antwort); value table SGBD";
CM_ SG_ 678 WISCHERPOTI "DSC_87.prg job STATUS_F_CAN_WISCHERTASTER result STAT_WISCHERPOTI (Status_Bit aus SG Antwort); value table SGBD";
CM_ BO_ 884 "MK60E5 FW 7846816A (M3): DSC TX, cycle 1000 ms | DSC DTC C997: C997 - (not receive message in administrable time) F-CAN SSL Radtoleranzabgleich, communication with DSC, Timeout [DE: C997 - F-CAN SZL Radtoleranzabgleich, Kommunikation mit DSC, Timeout (Nachricht in applizierbarer Zeit nicht empfangen)] (supervised: timeout) | DSC DTC C998: C998 - F-CAN SSL Radtoleranzabgleich plausibility, communication with DSC, Radtoleranzabgleich <-5% [DE: C998 - F-CAN SZL Radtoleranzabgleich Plausibilitaet, Kommunikation mit DSC, Radtoleranzabgleich < -5%] (supervised: range) | DSC DTC C99A: C99A - F-CAN SSL Radtoleranzabgleich plausibility, communication with DSC, Radtoleranzabgleich> 5% [DE: C99A - F-CAN SZL Radtoleranzabgleich Plausibilitaet, Kommunikation mit DSC, Radtoleranzabgleich > 5%] (supervised: range)";
CM_ SG_ 884 S374_b0 "MK60E5 FW 7846816A (M3) signal (internal var 0x15), meaning unknown";
CM_ SG_ 884 S374_b8 "MK60E5 FW 7846816A (M3) signal (internal var 0x0E), meaning unknown";
CM_ SG_ 884 S374_b16 "MK60E5 FW 7846816A (M3) signal (internal var 0x0F), meaning unknown";
CM_ SG_ 884 S374_b24 "MK60E5 FW 7846816A (M3) signal (internal var 0x10), meaning unknown";
CM_ SG_ 884 S374_b32 "MK60E5 FW 7846816A (M3) signal (internal var 0x11), meaning unknown";
CM_ BO_ 1934 "MK60E5 FW 7846816A (M3): DSC RX | Firmware comparison: not in MK60E5 FW 6862873A";
CM_ BO_ 1935 "MK60E5 FW 7846816A (M3): DSC RX | Firmware comparison: not in MK60E5 FW 6862873A";
CM_ BO_ 1936 "MK60E5 FW 7846816A (M3): DSC TX, event | Firmware comparison: not in MK60E5 FW 6862873A";
CM_ BO_ 1937 "MK60E5 FW 7846816A (M3): DSC TX, event | Firmware comparison: not in MK60E5 FW 6862873A";
CM_ BO_ 1943 "MK60E5 FW 7846816A (M3): DSC TX, event | Firmware comparison: not in MK60E5 FW 6862873A";
CM_ BO_ 1944 "MK60E5 FW 7846816A (M3): DSC TX, event | Firmware comparison: not in MK60E5 FW 6862873A";
CM_ BO_ 2004 "MK60E5 FW 7846816A (M3): DSC TX, event | Firmware comparison: not in MK60E5 FW 6862873A";
CM_ BO_ 2005 "MK60E5 FW 7846816A (M3): DSC TX, event | Firmware comparison: not in MK60E5 FW 6862873A";
CM_ BO_ 2006 "MK60E5 FW 7846816A (M3): DSC TX, event | Firmware comparison: not in MK60E5 FW 6862873A";
CM_ BO_ 2007 "MK60E5 FW 7846816A (M3): DSC TX, event | Firmware comparison: not in MK60E5 FW 6862873A";
CM_ BO_ 2008 "MK60E5 FW 7846816A (M3): DSC TX, event | Firmware comparison: not in MK60E5 FW 6862873A";
CM_ BO_ 2012 "MK60E5 FW 7846816A (M3): DSC RX | Firmware comparison: not in MK60E5 FW 6862873A";
CM_ BO_ 2013 "MK60E5 FW 7846816A (M3): DSC RX | Firmware comparison: not in MK60E5 FW 6862873A";
CM_ BO_ 2014 "MK60E5 FW 7846816A (M3): DSC RX | Firmware comparison: not in MK60E5 FW 6862873A";
CM_ BO_ 2015 "MK60E5 FW 7846816A (M3): DSC RX | Firmware comparison: not in MK60E5 FW 6862873A";
BA_DEF_ BO_ "GenMsgCycleTime" INT 0 65535;
BA_DEF_ BO_ "GenMsgSendType" ENUM "Cyclic","Event";
BA_DEF_ "BusType" STRING ;
BA_DEF_ "DBName" STRING ;
BA_DEF_DEF_ "GenMsgCycleTime" 0;
BA_DEF_DEF_ "GenMsgSendType" "Event";
BA_DEF_DEF_ "BusType" "CAN";
BA_DEF_DEF_ "DBName" "";
BA_ "DBName" "BMW_E9x_F_CAN";
BA_ "GenMsgCycleTime" BO_ 206 10;
BA_ "GenMsgSendType" BO_ 206 0;
BA_ "GenMsgCycleTime" BO_ 286 10;
BA_ "GenMsgSendType" BO_ 286 0;
BA_ "GenMsgCycleTime" BO_ 296 10;
BA_ "GenMsgSendType" BO_ 296 0;
BA_ "GenMsgCycleTime" BO_ 304 100;
BA_ "GenMsgSendType" BO_ 304 0;
BA_ "GenMsgCycleTime" BO_ 404 200;
BA_ "GenMsgSendType" BO_ 404 0;
BA_ "GenMsgCycleTime" BO_ 884 1000;
BA_ "GenMsgSendType" BO_ 884 0;
VAL_ 201 LW_OBEN_FEHLER 0 "in Ordnung" 1 "Radlenkwinkelverifizierung" 2 "Lenkwinkel_Rad-Signal fehlerhaft" 3 "Signal ungueltig" ;
VAL_ 280 LW_RAD_FEHLER 0 "in Ordnung" 1 "LWS Verifizierung" 2 "LWS-Signal fehlerhaft" 3 "Signal ungueltig" ;
VAL_ 404 OP_PUBU_CCTR_ACC 0 "nothing to do" 1 "tap forward, set / accelerate" 2 "overpress forward, step higher" 4 "tap backward, retard" 8 "overpress backward, step lower" 16 "tap up/down, off" 64 "tap axial, resume" 127 "signal invalid" ;
VAL_ 404 ABSTANDSWAHL_ACC 0 "Keine_Aktion" 1 "Tippen_nach_oben" 2 "Tippen_nach_unten" 3 "Signal_ungueltig" ;
VAL_ 404 MODUS_WAHL_CC_CA 0 "Taster_Mode_Wahl_nicht_gedrueckt" 1 "Taster_Mode_Wahl_gedrueckt" 3 "Signal_ungueltig" ;
VAL_ 470 TASTER_TELEFON 0 "Keine_Aktion" 1 "Taster_TEL_gedrueckt" 3 "Signal_ungueltig" ;
VAL_ 470 TASTER_AUDIO_LAUTSTAERKE 0 "Keine_Aktion" 1 "Lautstaerke_leiser" 2 "Lautstaerke_lauter" 3 "Signal_ungueltig" ;
VAL_ 470 TASTER_AUDIO_SUCHLAUF 0 "Keine_Aktion" 1 "Suchlauf_abwaerts" 2 "Suchlauf_aufwaerts" 3 "Signal_ungueltig" ;
VAL_ 470 TASTER_PUSH_TO_TALK 0 "Keine_Aktion" 1 "Taster_PTT_gedrueckt" 3 "Signal_ungueltig" ;
VAL_ 470 TASTER_SONDERFUNKTION 0 "Keine_Aktion" 1 "Taster_gedrueckt" 3 "Signal_ungueltig" ;
VAL_ 470 TASTER_PUSH_TO_HEAR 0 "Keine_Aktion" 1 "Taster_PTH_gedrueckt" 3 "Signal_ungueltig" ;
VAL_ 473 MDriveButton_inv 0 "Pressed" 1 "Not pressed" ;
VAL_ 473 MDriveButton 0 "Not pressed" 1 "Pressed" ;
VAL_ 678 WISCHERTASTER 0 "Keine_Aktion" 1 "Intervall/Automatik" 2 "Stufe_1" 3 "Stufe_2" 8 "Tippwischen" 16 "Frontwaschen" 64 "Heckwischen" 128 "Heckwaschen" 255 "Signal_ungueltig" ;
VAL_ 678 WISCHERPOTI 0 "Stufe_1" 1 "Stufe_2" 2 "Stufe_3" 4 "Stufe_4" 7 "Signal_ungueltig" ;
